# ISP6P5_H3A register map
Vendor: Texas Instruments
Peripheral module from a debugger description file (folder TDA2Px).
Registers are 32-bit, access per field, reset 0x0 unless marked. A register's access mark holds for its fields unless they carry their own. Offsets are as the file gives them; lines under a group give offsets from that group; [hi:lo] are bit positions; {n}, {i} and the like mark numbered series; 'fields as' and 'values as' point back to an identical list; <NAME> marks a mode.

## ISP6P5_H3A
0x00 H3A_PID ro reset not defined — Peripheral Revision and Class Information
  [31:0] REVISION — IP Revision
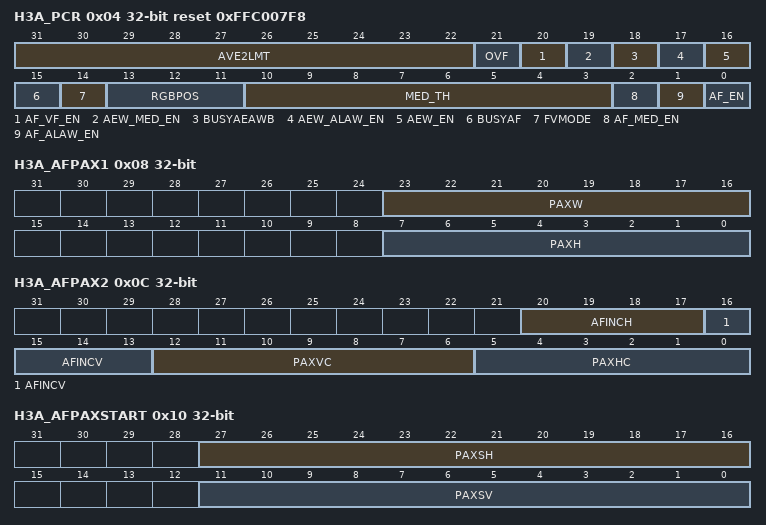
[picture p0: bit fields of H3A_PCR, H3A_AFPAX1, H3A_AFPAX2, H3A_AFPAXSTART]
0x04 H3A_PCR reset 0xFFC007F8 — Peripheral Control Register
  [31:22] AVE2LMT rw — AE/AWB Saturation Limit This is the value that all sub sampled pixels in the AE/AWB engine are compared to. If the data is greater or equal to this data then the block is considered saturated.
  [21] OVF rw — H3A module overflow status bit. If the H3A module overflows it will keep sending data. The software can read this status bit during vertical blanking period to ensure that no overflow happened while writing out the data to SDRAM. There is also an interrupt at ISP5 level (H3A_OVF) which can be used to monitor this.
    0=NEWENUM1 (Read 0: No overflow pending Write 0: Status bit unchanged); 1=NEWENUM2 (Read 1: Overflow happened while writing out the data. Output data likely to be corrupted. Write 1: Clear the status bit.)
  [20] AF_VF_EN rw — AF Vertical Focus Enable
    0=NEWENUM1 (4 Color Horizontal FV only); 1=NEWENUM2 (1 Color Horizontal FV and 1 Color Veritcal FV)
  [19] AEW_MED_EN rw — AE/AWB Median filter Enable If the median filter is enabled, then the 1st 2 and last 2 pixels in the frame are not filtered.
    0=NEWENUM1 (Disable Auto Focus median filter); 1=NEWENUM2 (Enable Auto Focus median filter)
  [18] BUSYAEAWB ro — Busy bit for AE/AWB
  [17] AEW_ALAW_EN rw — AE/AWB A-law Enable
    0=NEWENUM1 (Disable Auto exposure/white balance A-law table); 1=NEWENUM2 (Enable Auto exposure/white balance A-law table.)
  [16] AEW_EN rw — AE/AWB enable
    0=NEWENUM1 (Disable Auto exposure/white balance); 1=NEWENUM2 (Enable Auto exposure/white balance)
  [15] BUSYAF ro — Busy bit for AF.
  [14] FVMODE rw — Focus Value Accumulation Mode
    0=NEWENUM1 (Sum mode.); 1=NEWENUM2 (Peak mode.)
  [13:11] RGBPOS rw — Red, Green, and blue pixel location in the AF windows RGBPOS(0): GR and GB as Bayer pattern RGBPOS(1): RG and GB as Bayer pattern RGBPOS(2): GR and BG as Bayer pattern RGBPOS(3): RG and BG as Bayer pattern RGBPOS(4): GG and RB as custom pattern RGBPOS(5): RB and GG as custom pattern 6 and 7 are reserved This Value is only used if VF is disabled
  [10:3] MED_TH rw — Median filter threshold.
  [2] AF_MED_EN rw — Auto Focus Median filter Enable If the median filter is enabled, then the 1st 2 and last 2 pixels in the frame are not in the valid region. Therefore the paxel start/end and IIR filter start positions should not be set within the 1st and last 2 pixels.
    0=NEWENUM1 (Disable AF median filter.); 1=NEWENUM2 (Enable AF median filter.)
  [1] AF_ALAW_EN rw — AF A-law table enable
    0=NEWENUM1 (Disable Auto Focus A-law table); 1=NEWENUM2 (Enable Auto Focus A-law table)
  [0] AF_EN rw — AF enable
    0=NEWENUM1 (Disable Auto Focus Engine); 1=NEWENUM2 (Enable Auto Focus Engine)
0x08 H3A_AFPAX1 — Setup for the AF Engine Paxel Configuration
  [23:16] PAXW rw — AF Engine Paxel Width The width of the paxel is the value of this register plus 1 multiplied by 2. The minimum width is 16 pixels if pixel clock is ? or less of the vpss clock. If pixel clock is equal to vpss clock the minimum width is 32 pixels * This value is shadowed and latched on the rising edge of VSYNC.
  [7:0] PAXH rw — AF Engine Paxel Height The height of the paxel is the value of this register plus 1 multiplied by 2 with a final value of 2-256 (even) * This value is shadowed and latched on the rising edge of VSYNC.
0x0C H3A_AFPAX2 — Setup for the AF Engine Paxel Configuration
  [20:17] AFINCH rw — AF Engine Column Increments Number of columns to increment in a paxel plus 1 multiplied by 2. Thus, the number of columns that can be skipped between two processed line pairs is 2-32 (even). The starting two columns in a paxel are first processed before this field is applied. This must be set so that there are at least 4 samples on a line when combined with the number of horizontal paxels. * This value is shadowed and latched on the rising edge of VSYNC.
  [16:13] AFINCV rw — AF Engine Line Increments Number of lines to increment in a Paxel plus 1 multiplied by 2. Incrementing the line in a paxel is always done on a line pair due to the fact that the RGB pattern falls in two lines. If all the lines are to be processed, this field should be set to zero, and thus line count is incremented by 2 following a line pair. Thus, the number of lines that can be skipped between two processed line pairs is 0-30 (even). The starting two lines in a paxel are first processed before this field is applied. * This value is shadowed and latched on the rising edge of VSYNC.
  [12:6] PAXVC rw — AF Engine Vertical Paxel Count The number of paxels in the vertical direction plus 1. The maximum number of vertical paxels in a frame should not exceed 128. The value should be set to ensure that the bandwidth requirements and buffer size are not exceeded. * This value is shadowed and latched on the rising edge of VSYNC.
  [5:0] PAXHC rw — AF Engine Horizontal Paxel Count The number of paxels in the horizontal direction plus 1. It is illegal to set a number that is greater than 35 (total of 36 paxels in the horizontal direction). The minimum number of paxels should be 2 (valid range for the field is 1-35). * This value is shadowed and latched on the rising edge of VSYNC.
0x10 H3A_AFPAXSTART — Start Position for AF Engine Paxels
  [27:16] PAXSH rw — AF Engine Paxel Horizontal start position Range: 2-4094 PAXSH must be equal to or greater than (IIRSH + 2) This value must be even if Vertical mode is not enabled. If Vertical mode is enabled then the lower bit of PAXSH and IIRSH must be equal. * This value is shadowed and latched on the rising edge of VSYNC.
  [11:0] PAXSV rw — AF Engine Paxel Vertical start position Range: 0-4095 Sets the vertical line for the first paxel. This value must be greater then or equal to 8 if the vertical mode is enabled. * This value is shadowed and latched on the rising edge of VSYNC.
0x14 H3A_AFIIRSH — Start Position for IIRSH
  [11:0] IIRSH rw — AF Engine IIR Horizontal Start Position Range from 0-4094. When the horizontal position of a line equals this value the shift registers are cleared on the next pixel. This value must be even if Vertical mode is not enabled. If vertical mode is enabled then the lower bit must match the paxel horizontal start position. * This value is shadowed and latched on the rising edge of VSYNC.
0x18 H3A_AFBUFST — SDRAM destination address for AF engine statistics
  [31:5] AFBUFST rw — SDRAM destination address for AF engine statistics The SDRAM destination address for the AF statistics. The 6 LSBs are ignored, address shall be on a 64-byte boundary. This field can be altered even when the AF is busy. Change will take place only for the next frame. However, note that reading this register will always give the latest value.
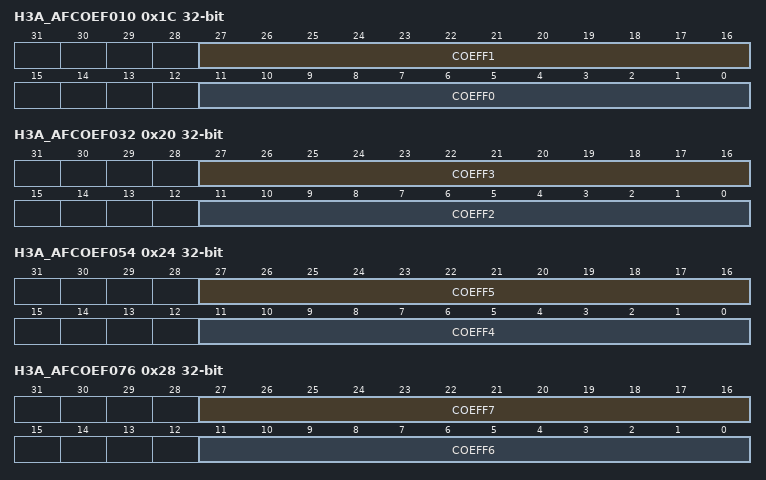
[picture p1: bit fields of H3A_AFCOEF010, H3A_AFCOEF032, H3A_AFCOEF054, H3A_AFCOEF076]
0x1C H3A_AFCOEF010 — IIR filter coefficient data for SET 0.
  [27:16] COEFF1 rw — AF Engine IIR filter Coefficient #1 (Set 0) The range is signed -32 = value = 31 +63/64
  [11:0] COEFF0 rw — AF Engine IIR filter Coefficient #0 (Set 0) The range is signed -32 = value = 31 +63/64
0x20 H3A_AFCOEF032 — IIR filter coefficient data for SET 0.
  [27:16] COEFF3 rw — AF Engine IIR filter Coefficient #3 (Set 0) The range is signed -32 = value = 31 +63/64
  [11:0] COEFF2 rw — AF Engine IIR filter Coefficient #2 (Set 0) The range is signed -32 = value = 31 +63/64
0x24 H3A_AFCOEF054 — IIR filter coefficient data for SET 0.
  [27:16] COEFF5 rw — AF Engine IIR filter Coefficient #5 (Set 0) The range is signed -32 = value = 31 +63/64
  [11:0] COEFF4 rw — AF Engine IIR filter Coefficient #4 (Set 0) The range is signed -32 = value = 31 +63/64
0x28 H3A_AFCOEF076 — IIR filter coefficient data for SET 0.
  [27:16] COEFF7 rw — AF Engine IIR filter Coefficient #7 (Set 0) The range is signed -32 = value = 31 +63/64
  [11:0] COEFF6 rw — AF Engine IIR filter Coefficient #6 (Set 0) The range is signed -32 = value = 31 +63/64
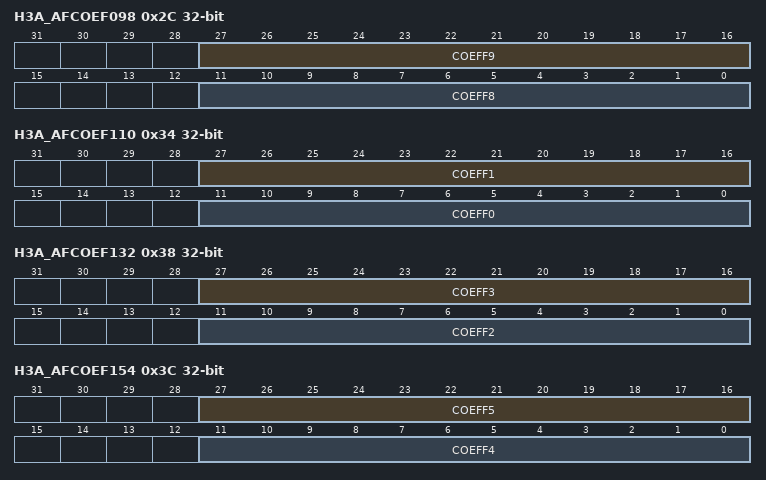
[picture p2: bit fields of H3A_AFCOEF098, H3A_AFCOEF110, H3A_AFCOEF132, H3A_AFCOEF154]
0x2C H3A_AFCOEF098 — IIR filter coefficient data for SET 0.
  [27:16] COEFF9 rw — AF Engine IIR filter Coefficient #9 (Set 0) The range is signed -32 = value = 31 +63/64
  [11:0] COEFF8 rw — AF Engine IIR filter Coefficient #8 (Set 0) The range is signed -32 = value = 31 +63/64
0x30 H3A_AFCOEF0010 — IIR filter coefficient data for SET 0.
  [11:0] COEFF10 rw — AF Engine IIR filter Coefficient #10 (Set 0) The range is signed -32 = value = 31 +63/64
0x34 H3A_AFCOEF110 — IIR filter coefficient data for SET 1.
  [27:16] COEFF1 rw — AF Engine IIR filter Coefficient #1 (Set 1) The range is signed -32 = value = 31 +63/64
  [11:0] COEFF0 rw — AF Engine IIR filter Coefficient #0 (Set 1) The range is signed -32 = value = 31 +63/64
0x38 H3A_AFCOEF132 — IIR filter coefficient data for SET 1.
  [27:16] COEFF3 rw — AF Engine IIR filter Coefficient #3 (Set 1) The range is signed -32 = value = 31 +63/64
  [11:0] COEFF2 rw — AF Engine IIR filter Coefficient #2 (Set 1) The range is signed -32 = value = 31 +63/64
0x3C H3A_AFCOEF154 — IIR filter coefficient data for SET 1.
  [27:16] COEFF5 rw — AF Engine IIR filter Coefficient #5 (Set 1) The range is signed -32 = value = 31 +63/64
  [11:0] COEFF4 rw — AF Engine IIR filter Coefficient #4 (Set 1) The range is signed -32 = value = 31 +63/64
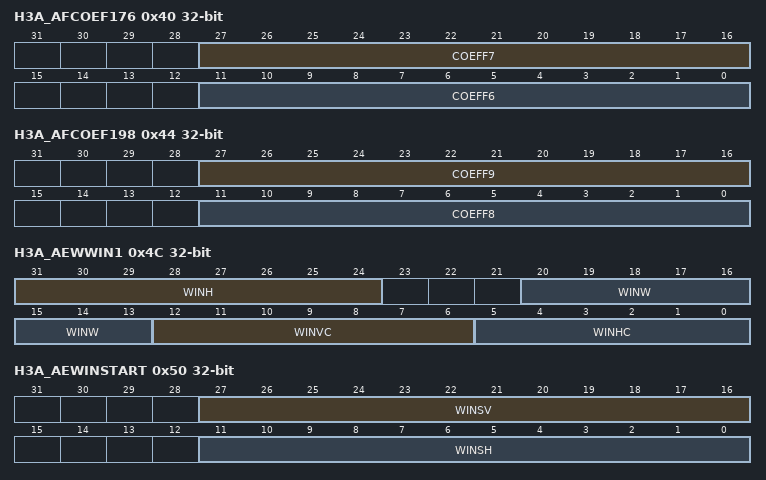
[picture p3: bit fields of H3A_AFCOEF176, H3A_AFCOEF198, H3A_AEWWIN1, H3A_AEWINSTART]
0x40 H3A_AFCOEF176 — IIR filter coefficient data for SET 1.
  [27:16] COEFF7 rw — AF Engine IIR filter Coefficient #7 (Set 1) The range is signed -32 = value = 31 +63/64
  [11:0] COEFF6 rw — AF Engine IIR filter Coefficient #6 (Set 1) The range is signed -32 = value = 31 +63/64
0x44 H3A_AFCOEF198 — IIR filter coefficient data for SET 1.
  [27:16] COEFF9 rw — AF Engine IIR filter Coefficient #9 (Set 1) The range is signed -32 = value = 31 +63/64
  [11:0] COEFF8 rw — AF Engine IIR filter Coefficient #8 (Set 1) The range is signed -32 = value = 31 +63/64
0x48 H3A_AFCOEF1010 — IIR filter coefficient data for SET 1.
  [11:0] COEFF10 rw — AF Engine IIR filter Coefficient #10 (Set 1) The range is signed -32 = value = 31 +63/64
0x4C H3A_AEWWIN1 — Configuration for AE/AWB Windows.
  [31:24] WINH rw — AE/AWB Engine Window Height This specifies the window height in an even number of pixels, the window height is the value plus 1 multiplied by 2. The final value can be from 2-512 (even) * This value is shadowed and latched on the rising edge of VSYNC.
  [20:13] WINW rw — AE/AWB Engine Window Width This specifies the window width in an even number of pixels, the window width is the value plus 1 multiplied by 2. The minimum width is expected to be 8 pixels. * This value is shadowed and latched on the rising edge of VSYNC.
  [12:6] WINVC rw — AE/AWB Engine Vertical Window Count The number of windows in the vertical direction plus 1. The maximum number of vertical windows in a frame should not exceed 128. The value should be set to ensure that the bandwidth requirements and buffer size are not exceeded * This value is shadowed and latched on the rising edge of VSYNC.
  [5:0] WINHC rw — AE/AWB Engine Horizontal Window Count The number of horizontal windows plus 1. The maximum number of horizontal windows is 35 plus 1 (36). The minimum number of windows should be 2 (valid range for the field is 1-35). * This value is shadowed and latched on the rising edge of VSYNC.
0x50 H3A_AEWINSTART — Start position for AE/AWB Windows.
  [27:16] WINSV rw — AE/AWB Engine Vertical Window Start Position Sets the first line for the first window. Range 0-4095 * This value is shadowed and latched on the rising edge of VSYNC.
  [11:0] WINSH rw — AE/AWB Engine Horizontal Window Start Position Sets the horizontal position for the first window on each line. Range 0-4095 * This value is shadowed and latched on the rising edge of VSYNC.
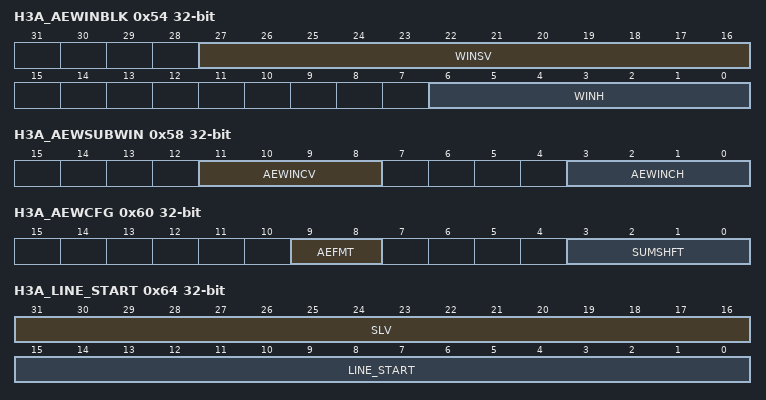
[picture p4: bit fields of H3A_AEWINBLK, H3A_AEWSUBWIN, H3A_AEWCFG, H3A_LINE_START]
0x54 H3A_AEWINBLK — Start position and height for black line of AE/AWB Windows
  [27:16] WINSV rw — AE/AWB Engine Vertical Window Start Position for single black line of windows Sets the first line for the single black line of windows. * This value is shadowed and latched on the rising edge of VSYNC. Range 0-4095 Note that the horizontal start and the horizontal number of windows will be similar to the regular windows
  [6:0] WINH rw — AE/AWB Engine Window Height for the single black line of windows This specifies the window height in an even number of pixels, the window height is the value plus 1 multiplied by 2. The final value can be from 2-256 (even) * This value is shadowed and latched on the rising edge of VSYNC.
0x58 H3A_AEWSUBWIN — Configuration for subsample data in AE/AWB window.
  [11:8] AEWINCV rw — AE/AWB Engine Vertical Sampling Point Increment Sets vertical distance between sub-samples within a window plus 1 multiplied by 2. The final range is 2-32. * This value is shadowed and latched on the rising edge of VSYNC.
  [3:0] AEWINCH rw — AE/AWB Engine Horizontal Sampling Point Increment Sets horizontal distance between sub-samples within a window plus 1 multiplied by 2. The final range is 2-32. * This value is shadowed and latched on the rising edge of VSYNC.
0x5C H3A_AEWBUFST — SDRAM destination address for AE/AWB engine statistics
  [31:5] AEWBUFST rw — SDRAM destination address for AE/AWB engine statistics The start location in SDRAM for the AE/AWB statistics. The 6 LSB are ignored, address should be on a 64-byte boundary This field can be altered even when the AE/AWB is busy. Change will take place only for the next frame. However, note that reading this register will always give the latest value.
0x60 H3A_AEWCFG — Configuration for AE/AWB
  [9:8] AEFMT rw — AE/AWB output format 0 = sum of squares 1 = min/max 2 = sum only; no sum of squares or min/max * This value is shadowed and latched on the rising edge of VSYNC
  [3:0] SUMSHFT rw — AE/AWB engine shift value for the accumulation of pixel values This bitfield sets the right shift value which is applied on the result of the pixel accumulation before it is stored in the packet. The accumulation takes place on 26 bits which is enough for 10-bit data and a maximum widow size of 512 x 512 which results into the accumulation of 256 x 256 pixels of the same color. The shift value shall be set such that the result fits on 16 bits. SUMSHFT = right shift value. Range: 0 -15 * This value is shadowed and latched on the rising edge of VSYNC
0x64 H3A_LINE_START rw — Line Framing Logic Register In certain cases the number of clock cycles between HD pulses will be greater than the line buffer included in the H3A module. The framing module prior to the line buffer enables to control the data which is input to the line buffer.
  [31:16] SLV — Start Line Vertical Specifies how many lines after the VD rising edge the real frame starts.
  [15:0] LINE_START — Line Start The framing module uses the LINE_START bitfield to find the position of the first pixel to place into the line buffer. Range: 0-65535
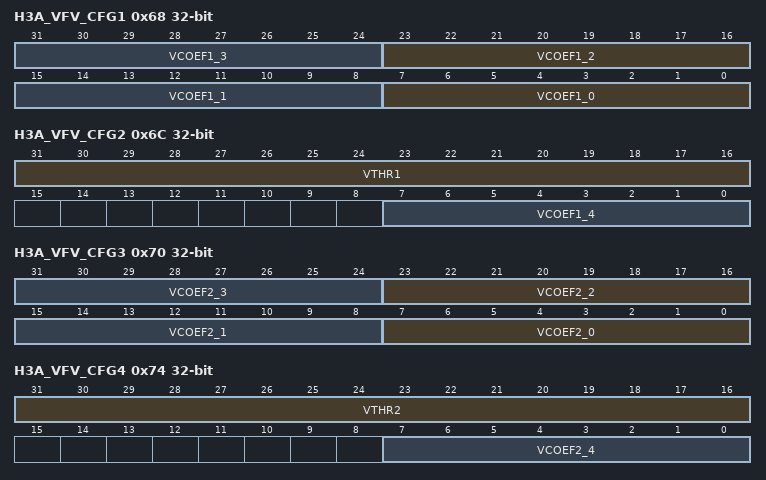
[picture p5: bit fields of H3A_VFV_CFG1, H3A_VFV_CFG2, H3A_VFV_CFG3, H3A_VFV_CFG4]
0x68 H3A_VFV_CFG1 rw — Vertical focus value configuration 1.
  [8n+7:8n] VCOEF1_{n} (n=0..3) — Vertical FV FIR 1 coefficient {n}
0x6C H3A_VFV_CFG2 — Vertical focus value configuration 2.
  [31:16] VTHR1 rw — Threshold for vertical FV FIR 1
  [7:0] VCOEF1_4 rw — Vertical FV FIR 1 coefficient 4
0x70 H3A_VFV_CFG3 rw — Vertical focus value configuration 4.
  [8n+7:8n] VCOEF2_{n} (n=0..3) — Vertical FV FIR 2 coefficient {n}
0x74 H3A_VFV_CFG4 — Vertical focus value configuration 4.
  [31:16] VTHR2 rw — Threshold for vertical FV FIR 2
  [7:0] VCOEF2_4 rw — Vertical FV FIR 2 coefficient 4
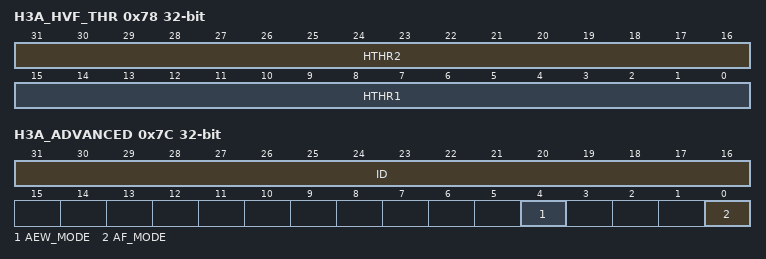
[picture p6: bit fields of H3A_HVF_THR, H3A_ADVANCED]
0x78 H3A_HVF_THR rw — Horizontal Focus Value Threshold
  [31:16] HTHR2 — Threshold for horizontal FV IIR 2
  [15:0] HTHR1 — Threshold for horizontal FV IIR 1
0x7C H3A_ADVANCED
  [31:16] ID rw — Below information should not be in TRM. To access the other bitfields (AF_MODE/AEW_MODE), certain value should be written to this ID field first. First, the ID is written to this field. Second, the AF_MODE or/and AEW_MODE is written.
    0=NEWENUM1 (This bit field shall be set to 0xCA00 to enable AF advanced mode. This bit field shall be set to 0xDC00 to enable AEW/AF advanced mode)
  [4] AEW_MODE rw — This bit should not be included in TRM. This bit is accesible only if ID is set to 0xDC00 AE/AWB engine custom mode (AVE2 mode) select
    0=NEWENUM1 (Normal Mode); 1=NEWENUM2 (Customer mode ID shall be set to 0xCA00 to enable this functionality.)
  [0] AF_MODE rw — AF engine mode. Below information should not be included in TRM. The effect of this bit changes based on the ID value. If other value than 0xCA00 or 0xDC00 is set to ID, this field has no effect.
    0=NEWENUM1 (Normal Mode); 1=NEWENUM2 (Advanced mode. ID shall be set to 0xCA00 or 0xDC00 to enable this functionality.)
